AUTOSAR XML (schema 00046)
package /TigerDetectionSW
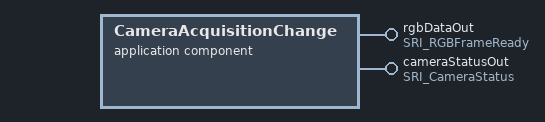
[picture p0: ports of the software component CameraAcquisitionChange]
  application sw component type CameraAcquisitionChange  # SW requirements: SWREQ_SEN_001, SWREQ_SEN_005, SWREQ_SEN_006, SWREQ_ODD_005, SWREQ_ODD_006.
    provide port rgbDataOut: provided-interface=SRI_RGBFrameReady  # SW requirements: SWREQ_SEN_001, SWREQ_SEN_004.
    provide port cameraStatusOut: provided-interface=SRI_CameraStatus  # SW requirements: SWREQ_SEN_005, SWREQ_SEN_006, SWREQ_ODD_005, SWREQ_ODD_006.
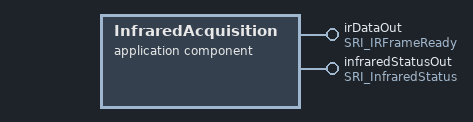
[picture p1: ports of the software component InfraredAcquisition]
  application sw component type InfraredAcquisition  # SW requirements: SWREQ_SEN_003, SWREQ_SEN_005, SWREQ_SEN_006, SWREQ_ODD_006, SWREQ_SEN_007.
    provide port irDataOut: provided-interface=SRI_IRFrameReady  # SW requirements: SWREQ_SEN_003, SWREQ_SEN_004, SWREQ_SEN_007.
    provide port infraredStatusOut: provided-interface=SRI_InfraredStatus  # SW requirements: SWREQ_SEN_005, SWREQ_SEN_006, SWREQ_ODD_006, SWREQ_SEN_007.
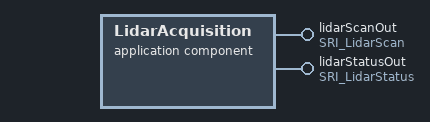
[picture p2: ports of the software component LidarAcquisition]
  application sw component type LidarAcquisition  # SW requirements: SWREQ_SEN_002, SWREQ_SEN_005, SWREQ_SEN_006, SWREQ_ODD_004, SWREQ_ODD_006.
    provide port lidarScanOut: provided-interface=SRI_LidarScan  # SW requirements: SWREQ_SEN_002, SWREQ_SEN_004.
    provide port lidarStatusOut: provided-interface=SRI_LidarStatus  # SW requirements: SWREQ_SEN_005, SWREQ_SEN_006, SWREQ_ODD_004, SWREQ_ODD_006.
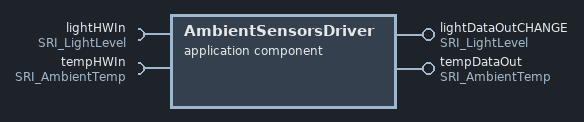
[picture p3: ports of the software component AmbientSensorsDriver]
  application sw component type AmbientSensorsDriver  # SW requirements: SWREQ_ODD_001.
    provide port lightDataOutCHANGE: provided-interface=SRI_LightLevel  # SW requirements: SWREQ_ODD_001.
    provide port tempDataOut: provided-interface=SRI_AmbientTemp  # SW requirements: SWREQ_ODD_001.
    require port lightHWIn: required-interface=SRI_LightLevel  # SW requirements: SWREQ_ODD_001.
    require port tempHWIn: required-interface=SRI_AmbientTemp  # SW requirements: SWREQ_ODD_001.
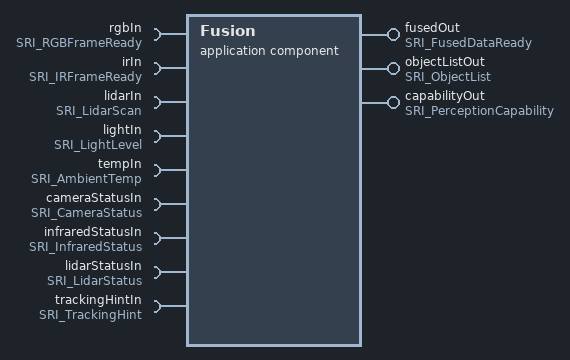
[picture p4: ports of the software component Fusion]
  application sw component type Fusion  # SW requirements: SWREQ_SEN_004, SWREQ_SEN_005, SWREQ_SEN_006, SWREQ_ALG_002, SWREQ_ODD_001, SWREQ_ODD_004, SWREQ_ODD_005, SWREQ_ODD_006, SWREQ_ENV_001, SWREQ_ENV_002, SWREQ_ENV_004, SWREQ_SEN_007.
    provide port fusedOut: provided-interface=SRI_FusedDataReady  # SW requirements: SWREQ_SEN_004, SWREQ_ALG_001, SWREQ_SEN_007.
    provide port objectListOut: provided-interface=SRI_ObjectList  # SW requirements: SWREQ_SEN_004, SWREQ_ALG_001, SWREQ_SEN_007.
    provide port capabilityOut: provided-interface=SRI_PerceptionCapability  # SW requirements: SWREQ_SEN_005, SWREQ_ODD_001, SWREQ_ODD_003, SWREQ_SM_005, SWREQ_SEN_007.
    9 x require port:
      rgbIn: required-interface=SRI_RGBFrameReady  # SW requirements: SWREQ_SEN_001, SWREQ_SEN_004.
      irIn: required-interface=SRI_IRFrameReady  # SW requirements: SWREQ_SEN_003, SWREQ_SEN_004, SWREQ_SEN_007.
      lidarIn: required-interface=SRI_LidarScan  # SW requirements: SWREQ_SEN_002, SWREQ_SEN_004.
      lightIn: required-interface=SRI_LightLevel  # SW requirements: SWREQ_ODD_001.
      tempIn: required-interface=SRI_AmbientTemp  # SW requirements: SWREQ_ODD_001.
      cameraStatusIn: required-interface=SRI_CameraStatus  # SW requirements: SWREQ_SEN_005, SWREQ_SEN_006, SWREQ_ODD_005, SWREQ_ODD_006.
      infraredStatusIn: required-interface=SRI_InfraredStatus  # SW requirements: SWREQ_SEN_005, SWREQ_SEN_006, SWREQ_ODD_006, SWREQ_SEN_007.
      lidarStatusIn: required-interface=SRI_LidarStatus  # SW requirements: SWREQ_SEN_005, SWREQ_SEN_006, SWREQ_ODD_004, SWREQ_ODD_006.
      trackingHintIn: required-interface=SRI_TrackingHint  # SW requirements: SWREQ_ALG_004, SWREQ_SEN_004.
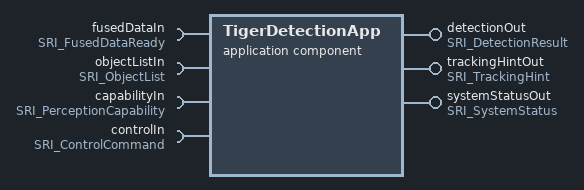
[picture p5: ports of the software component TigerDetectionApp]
  application sw component type TigerDetectionApp  # SW requirements: SWREQ_ALG_001, SWREQ_ALG_002, SWREQ_ALG_003, SWREQ_ALG_004, SWREQ_ALG_005, SWREQ_SM_001, SWREQ_SM_002, SWREQ_SM_003, SWREQ_SM_004, SWREQ_SM_005, SWREQ_ODD_002, SWREQ_ODD_003, SWREQ_ENV_001, SWREQ_ENV_002, SWREQ_ENV_003, SWREQ_ENV_004, SWREQ_SEN_007.
    provide port detectionOut: provided-interface=SRI_DetectionResult  # SW requirements: SWREQ_ALG_005, SWREQ_WRN_001, SWREQ_WRN_004, SWREQ_SEN_007.
    provide port trackingHintOut: provided-interface=SRI_TrackingHint  # SW requirements: SWREQ_ALG_004, SWREQ_SEN_004.
    provide port systemStatusOut: provided-interface=SRI_SystemStatus  # SW requirements: SWREQ_SM_004, SWREQ_SM_005, SWREQ_ODD_002, SWREQ_SEN_007.
    4 x require port:
      fusedDataIn: required-interface=SRI_FusedDataReady  # SW requirements: SWREQ_SEN_004, SWREQ_ALG_001, SWREQ_SEN_007.
      objectListIn: required-interface=SRI_ObjectList  # SW requirements: SWREQ_SEN_004, SWREQ_ALG_001, SWREQ_SEN_007.
      capabilityIn: required-interface=SRI_PerceptionCapability  # SW requirements: SWREQ_SEN_005, SWREQ_ODD_001, SWREQ_ODD_003, SWREQ_SM_005, SWREQ_SEN_007.
      controlIn: required-interface=SRI_ControlCommand  # SW requirements: SWREQ_SM_002, SWREQ_SM_003.
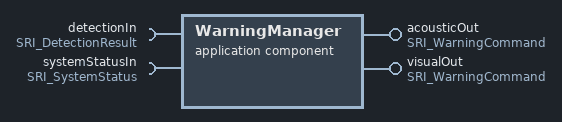
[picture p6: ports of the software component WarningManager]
  application sw component type WarningManager  # SW requirements: SWREQ_WRN_001, SWREQ_WRN_002, SWREQ_WRN_003, SWREQ_WRN_004, SWREQ_WRN_005, SWREQ_SM_005, SWREQ_ODD_002.
    provide port acousticOut: provided-interface=SRI_WarningCommand  # SW requirements: SWREQ_WRN_001, SWREQ_WRN_002, SWREQ_WRN_003, SWREQ_WRN_004, SWREQ_WRN_005, SWREQ_SM_005, SWREQ_ODD_002.
    provide port visualOut: provided-interface=SRI_WarningCommand  # SW requirements: SWREQ_WRN_001, SWREQ_WRN_002, SWREQ_WRN_003, SWREQ_WRN_004, SWREQ_WRN_005, SWREQ_SM_005, SWREQ_ODD_002.
    require port detectionIn: required-interface=SRI_DetectionResult  # SW requirements: SWREQ_ALG_005, SWREQ_WRN_001, SWREQ_WRN_004, SWREQ_SEN_007.
    require port systemStatusIn: required-interface=SRI_SystemStatus  # SW requirements: SWREQ_SM_004, SWREQ_SM_005, SWREQ_ODD_002, SWREQ_SEN_007.
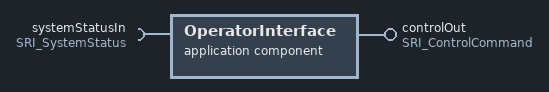
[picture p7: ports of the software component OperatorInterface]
  application sw component type OperatorInterface  # SW requirements: SWREQ_SM_002, SWREQ_SM_003, SWREQ_SM_004, SWREQ_SM_005, SWREQ_ODD_002.
    provide port controlOut: provided-interface=SRI_ControlCommand  # SW requirements: SWREQ_SM_002, SWREQ_SM_003.
    require port systemStatusIn: required-interface=SRI_SystemStatus  # SW requirements: SWREQ_SM_004, SWREQ_SM_005, SWREQ_ODD_002, SWREQ_SEN_007.
  composition sw component type TigerDetectionComposition
    8 x component:
      CameraAcquisitionChange_Instance: type=CameraAcquisitionChange
      InfraredAcquisition_Instance: type=InfraredAcquisition
      LidarAcquisition_Instance: type=LidarAcquisition
      AmbientSensorsDriver_Instance: type=AmbientSensorsDriver
      Fusion_Instance: type=Fusion
      TigerDetectionApp_Instance: type=TigerDetectionApp
      WarningManager_Instance: type=WarningManager
      OperatorInterface_Instance: type=OperatorInterface
    connect CameraAcquisitionChange_Instance.rgbDataOut -> Fusion_Instance.rgbIn
    connect InfraredAcquisition_Instance.irDataOut -> Fusion_Instance.irIn
    connect InfraredAcquisition_Instance.infraredStatusOut -> Fusion_Instance.infraredStatusIn
    connect CameraAcquisitionChange_Instance.cameraStatusOut -> Fusion_Instance.cameraStatusIn
    connect LidarAcquisition_Instance.lidarScanOut -> Fusion_Instance.lidarIn
    connect LidarAcquisition_Instance.lidarStatusOut -> Fusion_Instance.lidarStatusIn
    connect AmbientSensorsDriver_Instance.lightDataOutCHANGE -> Fusion_Instance.lightIn
    connect AmbientSensorsDriver_Instance.tempDataOut -> Fusion_Instance.tempIn
    connect Fusion_Instance.fusedOut -> TigerDetectionApp_Instance.fusedDataIn
    connect Fusion_Instance.objectListOut -> TigerDetectionApp_Instance.objectListIn
    connect Fusion_Instance.capabilityOut -> TigerDetectionApp_Instance.capabilityIn
    connect OperatorInterface_Instance.controlOut -> TigerDetectionApp_Instance.controlIn
    connect TigerDetectionApp_Instance.systemStatusOut -> OperatorInterface_Instance.systemStatusIn
    connect TigerDetectionApp_Instance.systemStatusOut -> WarningManager_Instance.systemStatusIn
    connect TigerDetectionApp_Instance.detectionOut -> WarningManager_Instance.detectionIn
    connect TigerDetectionApp_Instance.trackingHintOut -> Fusion_Instance.trackingHintIn
